# AVR32SD32 register map
Vendor: Atmel; File version: 1.0
CPU: other r0p0, little endian, no MPU, no FPU, 4 interrupt priority bits
Registers are 8-bit, read-write, reset 0x0 unless marked. A register's access mark holds for its fields unless they carry their own. Offsets are from the block's base; [hi:lo] are bit positions; {n}, {i} and the like mark numbered series.

## SIGROW — Signature row
Base 0x00801080
{0x0+i} DEVICEID{i} ro (i=0..2) — Device ID Byte {i}
0x04 TEMPSENSE0 16-bit ro (reset mask 0xFF) — Temperature Calibration 0
0x06 TEMPSENSE1 16-bit ro (reset mask 0xFF) — Temperature Calibration 1
{0x10+i} SERNUM{i} ro (i=0..5) — LOTNUM{i}
0x16 SERNUM6 ro — RANDOM
0x17 SERNUM7 ro — SCRIBE
0x18 SERNUM8 ro — XPOS0
0x19 SERNUM9 ro — XPOS1
0x1A SERNUM10 ro — YPOS0
0x1B SERNUM11 ro — YPOS1
{0x10+i} SERNUM{i} ro (i=12..15) — RES{i-12}

## SLPCTRL — Sleep Controller
Base 0x00800050
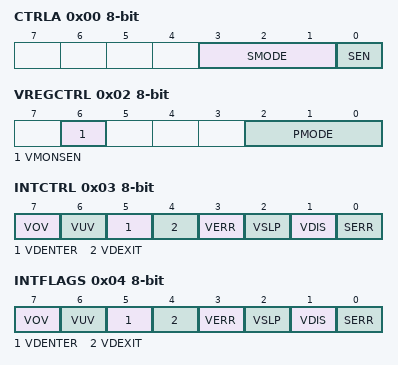
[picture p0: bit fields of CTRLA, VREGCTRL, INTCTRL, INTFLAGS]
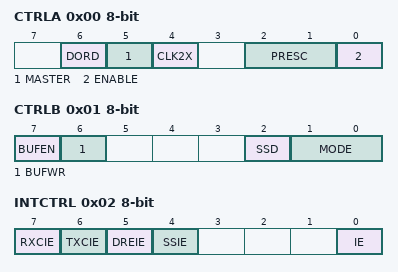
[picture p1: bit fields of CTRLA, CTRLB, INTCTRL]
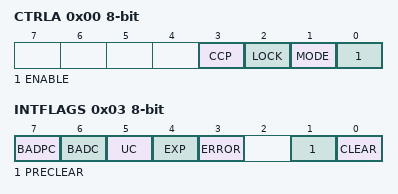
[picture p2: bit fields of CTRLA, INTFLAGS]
0x00 CTRLA — Control A
  [3:1] SMODE — Sleep mode
    0=IDLE (Idle mode); 1=STDBY (Standby Mode); 2=PDOWN (Power-down Mode)
  [0] SEN — Sleep enable
0x01 CTRLB wo — Control B
  [1:0] DMODE — VMON Diagnostic Mode
    0=NO (No VMON error should be detected); 1=UNDER (VMON Undervoltage error should be detected); 2=OVER (VMON Overvoltage error should be detected)
0x02 VREGCTRL — Voltage Regulator Control
  [6] VMONSEN — VMON Sleep Mode Enable
    0=DISABLE (VMON disabled in STANDBY); 1=ENABLE (VMON enabled in STANDBY)
  [2:0] PMODE — Performance Mode
    0=AUTO (Automatically switch from LDO to to ULP regulator in sleep and when running on 32.768 kHz oscillator); 1=FULL (Run on LDO in all modes)
0x03 INTCTRL — Interrupt Control
  [7] VOV — VMON Overvoltage Detected
  [6] VUV — VMON Undervoltage Detected
  [5] VDENTER — VMON Diagnostic Mode Enter
  [4] VDEXIT — VMON Diagnostic Mode Exit
  [3] VERR — VMON Error
  [2] VSLP — VMON is in Sleep Mode
  [1] VDIS — VMON is Disabled
  [0] SERR — Sleep Error
0x04 INTFLAGS — Interrup Status
  [7] VOV — VMON Overvoltage Detected
  [6] VUV — VMON Undervoltage Detected
  [5] VDENTER — VMON Diagnostic Mode Enter
  [4] VDEXIT — VMON Diagnostic Mode Exit
  [3] VERR — VMON has an internal error
  [2] VSLP — VMON is in Sleep Mode
  [1] VDIS — VMON is Disabled
  [0] SERR — Sleep Error

## SPI0 — Serial Peripheral Interface
Base 0x00800940
Same registers: SPI1 0x00800960
0x00 CTRLA — Control A
  [6] DORD — Data Order Setting
  [5] MASTER — Host Operation Enable
  [4] CLK2X — Enable Double Speed
  [2:1] PRESC — Prescaler
    0=DIV4 (CLK_PER / 4); 1=DIV16 (CLK_PER / 16); 2=DIV64 (CLK_PER / 64); 3=DIV128 (CLK_PER / 128)
  [0] ENABLE — Enable Module
0x01 CTRLB — Control B
  [7] BUFEN — Buffer Mode Enable
  [6] BUFWR — Buffer Mode Wait for Receive
  [2] SSD — SPI Select Disable
  [1:0] MODE — SPI Mode
    {v}=SPI Mode {v} (v=0..3)
0x02 INTCTRL — Interrupt Control
  [7] RXCIE — Receive Complete Interrupt Enable
  [6] TXCIE — Transfer Complete Interrupt Enable
  [5] DREIE — Data Register Empty Interrupt Enable
  [4] SSIE — SPI Select Trigger Interrupt Enable
  [0] IE — Interrupt Enable
0x03 INTFLAGS — Interrupt Flags
  [7] IF — Interrupt Flag
  [7] RXCIF — Receive Complete Interrupt Flag
  [6] TXCIF — Transfer Complete Interrupt Flag
  [6] WRCOL — Write Collision
  [5] DREIF — Data Register Empty Interrupt Flag
  [4] SSIF — SPI Select Trigger Interrupt Flag
  [0] BUFOVF — Buffer Overflow
0x04 DATA

## SWDT — Synchronous Watchdog Timer
Base 0x00800E20
0x00 CTRLA — Control A
  [3] CCP — SWDT Register Lock
  [2] LOCK
    0=UNLOCKED (SWDT SFRs are not LOCK-Protected); 1=LOCKED (SWDT SFRs are LOCK-Protected)
  [1] MODE — Peripheral Mode
    0=CLOCK (SWDT counts clock cycles); 1=INSTRUCTION (SWDT counts executed instructions)
  [0] ENABLE — Peripheral Enable
0x01 CTRLB wo — Control B
  [0] TEST
0x02 INTCTRL — Interrupt Control
  [3] ERROR — SWDT Error interrupt enable
0x03 INTFLAGS — Interrupt Flags
  [7] BADPC ro — Non-PRECLEAR Command received while expecting PRECLEAR
  [6] BADC ro — Non-CLEAR Command received while expecting CLEAR
  [5] UC ro — Unexpected Command
  [4] EXP ro — Counter has expired
  [3] ERROR — SWDT Error has occured
  [1] PRECLEAR ro — Preclear Ready
  [0] CLEAR ro — Clear Ready
0x04 CNT 32-bit ro (reset mask 0xFF) — Counter
  [23:0] CNT — SWDT Counter
0x08 RESET 32-bit (reset mask 0xFF) — Counter Reset
  [23:0] RESET — SWDT Counter Reset Value
0x0C WINDOW 16-bit (reset mask 0xFF) — Counter Window
0x0E COMMAND wo
  [7:0] COMMAND — SWDT Command
    8=PRECLEAR (Step 1 in the SWDT clear sequence); 16=CLEAR (Step 2 in the SWDT clear sequence)
